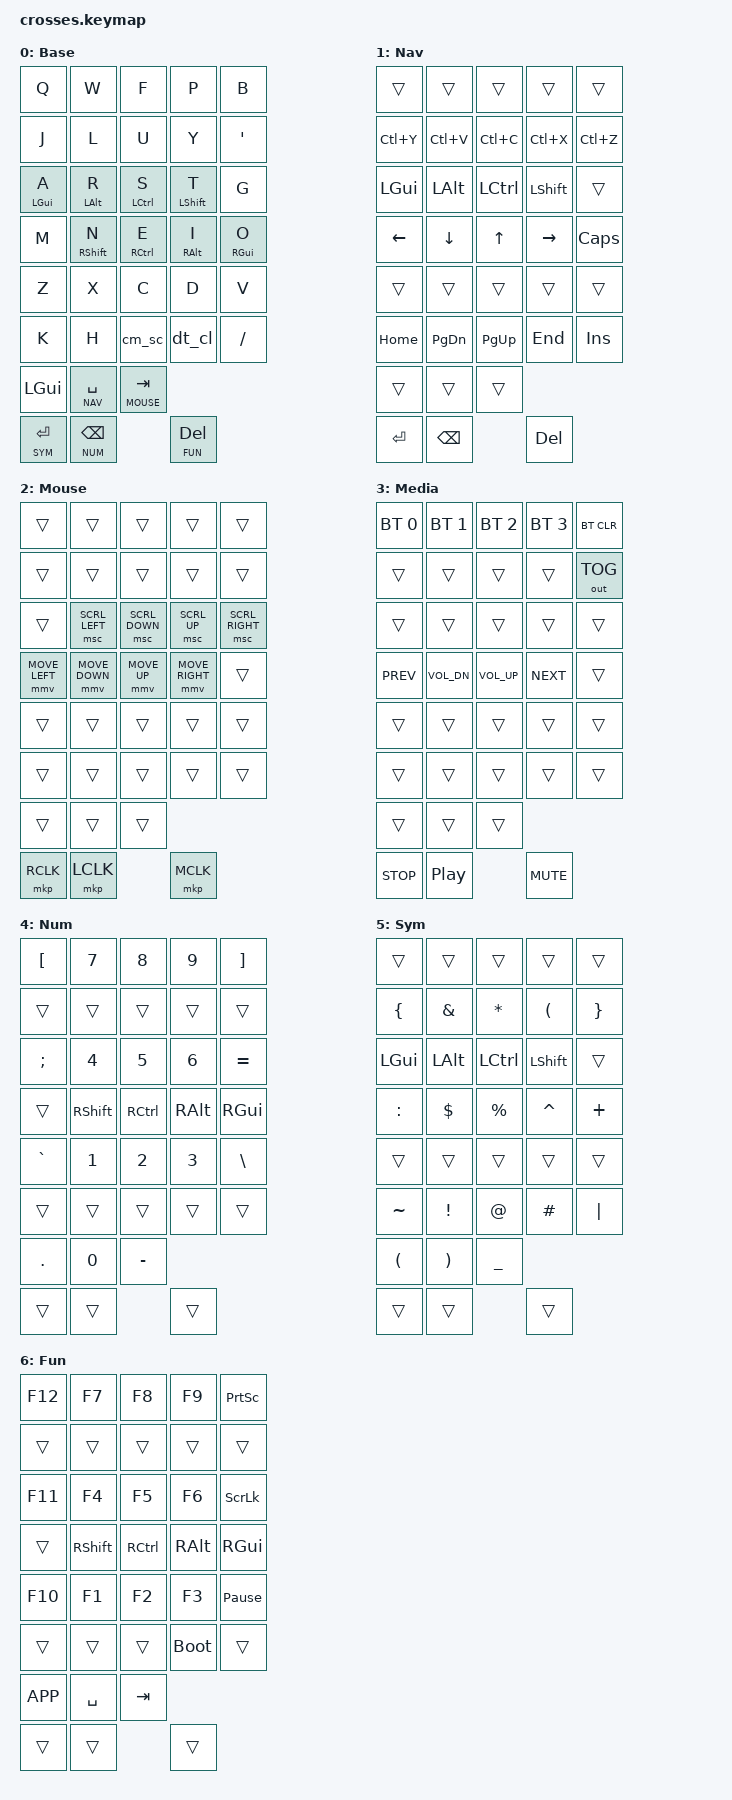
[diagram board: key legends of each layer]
#include <behaviors.dtsi>
#include <dt-bindings/zmk/keys.h>
#include <dt-bindings/zmk/bt.h>
#include <dt-bindings/zmk/mouse.h>
#include <dt-bindings/zmk/outputs.h>

#define BASE   0
#define NAV    1
#define MOUSE  2
#define MEDIA  3
#define NUM    4
#define SYM    5
#define FUN    6

/ {
    behaviors {
        hm: homerow_mod {
            compatible = "zmk,behavior-hold-tap";
            #binding-cells = <2>;
            tapping-term-ms = <280>;
            quick-tap-ms = <175>;
            require-prior-idle-ms = <150>;
            flavor = "balanced";
            bindings = <&kp>, <&kp>;
        };

        lt_t: layer_tap_thumb {
            compatible = "zmk,behavior-hold-tap";
            #binding-cells = <2>;
            tapping-term-ms = <200>;
            quick-tap-ms = <175>;
            flavor = "balanced";
            bindings = <&mo>, <&kp>;
        };

        cm_sc: comma_semi {
            compatible = "zmk,behavior-mod-morph";
            #binding-cells = <0>;
            bindings = <&kp COMMA>, <&kp SEMI>;
            mods = <(MOD_LSFT|MOD_RSFT)>;
        };

        dt_cl: dot_colon {
            compatible = "zmk,behavior-mod-morph";
            #binding-cells = <0>;
            bindings = <&kp DOT>, <&kp COLON>;
            mods = <(MOD_LSFT|MOD_RSFT)>;
        };
    };

    combos {
        compatible = "zmk,combos";

        combo_esc {
            timeout-ms = <40>;
            key-positions = <0 10>;
            bindings = <&kp ESC>;
        };

        combo_ret {
            timeout-ms = <40>;
            key-positions = <21 22>;
            bindings = <&kp RET>;
        };

        combo_caps {
            timeout-ms = <50>;
            key-positions = <16 19>;
            bindings = <&caps_word>;
        };
    };

    conditional_layers {
        compatible = "zmk,conditional-layers";
        tri_media {
            if-layers = <NAV MOUSE>;
            then-layer = <MEDIA>;
        };
    };

    keymap {
        compatible = "zmk,keymap";

        base_layer {
            label = "Base";
            bindings = 
                &kp Q        &kp W        &kp F        &kp P        &kp B
                &kp J        &kp L        &kp U        &kp Y        &kp SQT
                &hm LGUI A   &hm LALT R   &hm LCTRL S  &hm LSHFT T  &kp G
                &kp M        &hm RSHFT N  &hm RCTRL E  &hm RALT I   &hm RGUI O
                &kp Z        &kp X        &kp C        &kp D        &kp V
                &kp K        &kp H        &cm_sc       &dt_cl       &kp FSLH
                &kp LGUI     &lt_t NAV SPACE    &lt_t MOUSE TAB
                &lt_t SYM RET    &lt_t NUM BSPC    &lt_t FUN DEL
            >;
        };

        nav_layer {
            label = "Nav";
            bindings = 
                &trans    &trans     &trans     &trans    &trans
                &kp LC(Y) &kp LC(V)  &kp LC(C)  &kp LC(X) &kp LC(Z)
                &kp LGUI  &kp LALT   &kp LCTRL  &kp LSHFT &trans
                &kp LEFT  &kp DOWN   &kp UP     &kp RIGHT &kp CAPS
                &trans    &trans     &trans     &trans    &trans
                &kp HOME  &kp PG_DN  &kp PG_UP  &kp END   &kp INS
                &trans    &trans     &trans
                &kp RET   &kp BSPC   &kp DEL
            >;
        };

        mouse_layer {
            label = "Mouse";
            bindings = 
                &trans          &trans          &trans        &trans          &trans
                &trans          &trans          &trans        &trans          &trans
                &trans          &msc SCRL_LEFT  &msc SCRL_DOWN &msc SCRL_UP  &msc SCRL_RIGHT
                &mmv MOVE_LEFT  &mmv MOVE_DOWN  &mmv MOVE_UP  &mmv MOVE_RIGHT &trans
                &trans          &trans          &trans        &trans          &trans
                &trans          &trans          &trans        &trans          &trans
                &trans          &trans          &trans
                &mkp RCLK       &mkp LCLK       &mkp MCLK
            >;
        };

        media_layer {
            label = "Media";
            bindings = 
                &bt BT_SEL 0  &bt BT_SEL 1  &bt BT_SEL 2  &bt BT_SEL 3  &bt BT_CLR
                &trans        &trans        &trans        &trans        &out OUT_TOG
                &trans        &trans        &trans        &trans        &trans
                &kp C_PREV    &kp C_VOL_DN  &kp C_VOL_UP  &kp C_NEXT    &trans
                &trans        &trans        &trans        &trans        &trans
                &trans        &trans        &trans        &trans        &trans
                &trans        &trans        &trans
                &kp C_STOP    &kp C_PP      &kp C_MUTE
            >;
        };

        num_layer {
            label = "Num";
            bindings = 
                &kp LBKT   &kp N7  &kp N8  &kp N9  &kp RBKT
                &trans     &trans  &trans  &trans  &trans
                &kp SEMI   &kp N4  &kp N5  &kp N6  &kp EQUAL
                &trans     &kp RSHFT  &kp RCTRL  &kp RALT  &kp RGUI
                &kp GRAVE  &kp N1  &kp N2  &kp N3  &kp BSLH
                &trans     &trans  &trans  &trans  &trans
                &kp DOT    &kp N0  &kp MINUS
                &trans     &trans  &trans
            >;
        };

        sym_layer {
            label = "Sym";
            bindings = 
                &trans    &trans    &trans    &trans    &trans
                &kp LBRC  &kp AMPS  &kp STAR  &kp LPAR  &kp RBRC
                &kp LGUI  &kp LALT  &kp LCTRL &kp LSHFT &trans
                &kp COLON &kp DLLR  &kp PRCNT &kp CARET &kp PLUS
                &trans    &trans    &trans    &trans    &trans
                &kp TILDE &kp EXCL  &kp AT    &kp HASH  &kp PIPE
                &kp LPAR  &kp RPAR  &kp UNDER
                &trans    &trans    &trans
            >;
        };

        fun_layer {
            label = "Fun";
            bindings = 
                &kp F12  &kp F7  &kp F8  &kp F9  &kp PSCRN
                &trans   &trans  &trans  &trans  &trans
                &kp F11  &kp F4  &kp F5  &kp F6  &kp SLCK
                &trans   &kp RSHFT  &kp RCTRL  &kp RALT  &kp RGUI
                &kp F10  &kp F1  &kp F2  &kp F3  &kp PAUSE_BREAK
                &trans   &trans  &trans  &bootloader  &trans
                &kp K_APP  &kp SPACE  &kp TAB
                &trans     &trans     &trans
            >;
        };
    };
};
